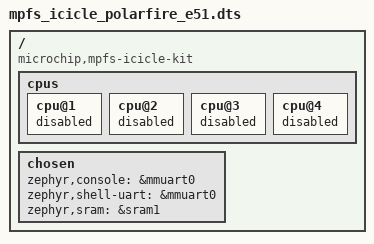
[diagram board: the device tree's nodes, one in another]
/dts-v1/;
#include "mpfs_icicle_common.dtsi"

/ {
	compatible = "microchip,mpfs-icicle-kit", "microchip,mpfs";

	cpus {
		cpu@1 {
			status = "disabled";
		};

		cpu@2 {
			status = "disabled";
		};

		cpu@3 {
			status = "disabled";
		};

		cpu@4 {
			status = "disabled";
		};
	};

	chosen {
		zephyr,console = &mmuart0;
		zephyr,shell-uart = &mmuart0;
		zephyr,sram = &sram1;
	};
};
